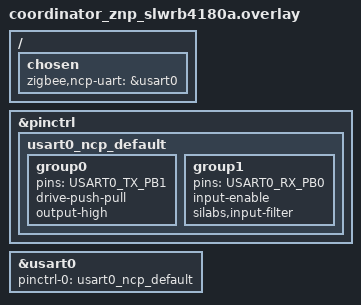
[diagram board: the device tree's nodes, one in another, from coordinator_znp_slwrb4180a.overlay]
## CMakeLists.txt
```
# SPDX-FileCopyrightText: Copyright The Zephyr Project Contributors
# SPDX-License-Identifier: Apache-2.0
cmake_minimum_required(VERSION 3.20)
find_package(Zephyr REQUIRED HINTS $ENV{ZEPHYR_BASE})
project(zigbee_shell)
target_sources(app PRIVATE
  src/main.c
  src/app_bdb.c
  src/app_profile.c
)

if(CONFIG_BOARD_PROMICRO_NRF52840 AND CONFIG_SHELL)
  target_sources(app PRIVATE src/board_promicro_nrf52840.c)
endif()

if(CONFIG_BOARD_WEACT_STM32WB55_CORE)
  # USB CDC console and mcumgr, watchdog and the flash state fix of the board; the same
  # fix is built into its MCUboot, see mcuboot/
  if(CONFIG_USB_DEVICE_STACK_NEXT)
    include(${ZEPHYR_BASE}/samples/subsys/usb/common/common.cmake)
  endif()
  target_sources(app PRIVATE
    src/board_weact_stm32wb55_core.c
    mcuboot/wbfix/wbfix.c
  )
endif()

# Expose ZCL SDK headers (zcl/, af/) that live under subsys/zigbee but are
# not part of the public zephyr_include_directories set.
target_include_directories(app PRIVATE
    ${ZEPHYR_BASE}/subsys/zigbee
    ${ZEPHYR_BASE}/subsys/zigbee/include
    ${ZEPHYR_BASE}/subsys/zigbee/common/includes
    ${ZEPHYR_BASE}/subsys/zigbee/platform/zephyr
)
```

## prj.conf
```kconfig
# SPDX-FileCopyrightText: Copyright The Zephyr Project Contributors
# SPDX-License-Identifier: Apache-2.0

CONFIG_ZIGBEE=y
CONFIG_ZIGBEE_ED=y
CONFIG_ZIGBEE_BDB=y
CONFIG_ZIGBEE_ZCL=y
CONFIG_ZIGBEE_GP=n
CONFIG_ZIGBEE_OTA=n
CONFIG_ZIGBEE_WWAH=n
# k_sys_fatal_error_handler() reboots instead of spinning forever on a
# fault/assert -- required so SYSTEM_RESET() (zb_main.c) links.
CONFIG_REBOOT=y
CONFIG_NETWORKING=y
CONFIG_NET_L2_CUSTOM_IEEE802154=y
CONFIG_NET_TC_RX_COUNT=0
CONFIG_NET_IPV4=n
CONFIG_NET_IPV6=n
CONFIG_NET_UDP=n
CONFIG_NET_TCP=n
CONFIG_NET_SOCKETS=n
CONFIG_IEEE802154=y
CONFIG_IEEE802154_L2_PKT_INCL_FCS=n
CONFIG_CONSOLE=n
CONFIG_UART_CONSOLE=n
CONFIG_SERIAL=n
CONFIG_PRINTK=n
CONFIG_NVS=y
CONFIG_FLASH=y
CONFIG_FLASH_MAP=y
CONFIG_LOG=n
CONFIG_MAIN_STACK_SIZE=896
CONFIG_SYSTEM_WORKQUEUE_STACK_SIZE=1024
# Keep the packet pools small; Zigbee consumes RX packets in its own thread.
CONFIG_NET_BUF_RX_COUNT=2
CONFIG_NET_BUF_TX_COUNT=2
```

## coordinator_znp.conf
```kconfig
# SPDX-FileCopyrightText: Copyright The Zephyr Project Contributors
# SPDX-License-Identifier: Apache-2.0

# A coordinator that a Z-Stack host (Zigbee2MQTT, ZHA) drives over the UART
# the board overlay names as zigbee,ncp-uart.
CONFIG_ZIGBEE_COORDINATOR=y
CONFIG_ZIGBEE_NCP=y
CONFIG_ZIGBEE_NCP_ZSTACK=y
CONFIG_ZIGBEE_STACK_SIZE=4096
```

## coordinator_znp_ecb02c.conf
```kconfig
# SPDX-FileCopyrightText: Copyright The Zephyr Project Contributors
# SPDX-License-Identifier: Apache-2.0

# The console UART is the host UART: no shell and no log on it
CONFIG_SHELL=n
CONFIG_KERNEL_SHELL=n

# The UART has a 16-byte receive FIFO: collect the requests in the interrupt
CONFIG_ZIGBEE_NCP_ZSTACK_UART_IRQ=y
```

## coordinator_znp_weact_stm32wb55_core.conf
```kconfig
# SPDX-FileCopyrightText: Copyright The Zephyr Project Contributors
# SPDX-License-Identifier: Apache-2.0

# The first USB CDC port is the host UART: no console, shell or log on it
CONFIG_SHELL=n
CONFIG_SHELL_BACKEND_SERIAL=n
CONFIG_SHELL_LOG_BACKEND=n
CONFIG_LOG=n
CONFIG_CONSOLE=n
CONFIG_PRINTK=n
```

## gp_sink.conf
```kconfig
# SPDX-FileCopyrightText: Copyright The Zephyr Project Contributors
# SPDX-License-Identifier: Apache-2.0

# Green Power proxy and sink; use with router.conf.
CONFIG_ZIGBEE_GP=y
CONFIG_ZIGBEE_GP_SINK=y
CONFIG_GPIO=y
```

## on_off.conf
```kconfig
# SPDX-FileCopyrightText: Copyright The Zephyr Project Contributors
# SPDX-License-Identifier: Apache-2.0

# On/Off light server driving led0.
CONFIG_ZIGBEE_ZCL_ON_OFF=y
CONFIG_GPIO=y
```

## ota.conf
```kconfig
# SPDX-FileCopyrightText: Copyright The Zephyr Project Contributors
# SPDX-License-Identifier: Apache-2.0

# Use together with -S tlsr8258-mcuboot.
CONFIG_ZIGBEE_OTA=y
CONFIG_LOG=y
```

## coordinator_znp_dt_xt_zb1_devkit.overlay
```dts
/*
 * SPDX-FileCopyrightText: Copyright The Zephyr Project Contributors
 * SPDX-License-Identifier: Apache-2.0
 */

/* Z-Stack host UART for dt_xt_zb1_devkit: uart0 (GPIO14 TX, GPIO15 RX), the
 * board's only UART. The coordinator build turns the console off, so the UART
 * carries only the NCP protocol.
 */

/ {
	chosen {
		zigbee,ncp-uart = &uart0;
	};
};
```

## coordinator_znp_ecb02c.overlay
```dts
/*
 * SPDX-FileCopyrightText: Copyright The Zephyr Project Contributors
 * SPDX-License-Identifier: Apache-2.0
 */

/* Z-Stack host UART for ecb02c: uart1 (P3 TX, P2 RX), the module's console UART and the one its
 * USB-UART is wired to. The coordinator build turns the console and the shell off, so the UART
 * carries only the NCP protocol.
 */

/ {
	chosen {
		zigbee,ncp-uart = &uart1;
	};
};
```

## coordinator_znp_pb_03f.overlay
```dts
/*
 * SPDX-FileCopyrightText: Copyright The Zephyr Project Contributors
 * SPDX-License-Identifier: Apache-2.0
 */

/* Z-Stack host UART for pb_03f: uart0, the board's only UART. The coordinator
 * build turns the console off, so the UART carries only the NCP protocol.
 */

/ {
	chosen {
		zigbee,ncp-uart = &uart0;
	};
};
```

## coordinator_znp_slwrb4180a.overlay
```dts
/*
 * SPDX-FileCopyrightText: Copyright The Zephyr Project Contributors
 * SPDX-License-Identifier: Apache-2.0
 */

/* Z-Stack host UART for slwrb4180a: USART0 on PB0 (RX) and PB1 (TX). The
 * coordinator build turns the console off, so the UART carries only the NCP
 * protocol. Router and end device builds keep the board's default pins.
 */

#include <zephyr/dt-bindings/pinctrl/silabs/xg21-pinctrl.h>

&pinctrl {
	usart0_ncp_default: usart0_ncp_default {
		group0 {
			pins = <USART0_TX_PB1>;
			drive-push-pull;
			output-high;
		};

		group1 {
			pins = <USART0_RX_PB0>;
			input-enable;
			silabs,input-filter;
		};
	};
};

&usart0 {
	pinctrl-0 = <&usart0_ncp_default>;
	pinctrl-names = "default";
};

/ {
	chosen {
		zigbee,ncp-uart = &usart0;
	};
};
```

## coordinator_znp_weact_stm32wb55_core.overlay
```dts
/*
 * SPDX-FileCopyrightText: Copyright The Zephyr Project Contributors
 * SPDX-License-Identifier: Apache-2.0
 */

/* The first USB CDC port carries the Z-Stack host protocol of coordinator_znp.conf: the board
 * is a USB coordinator. The second one stays the mcumgr port.
 */
/ {
	chosen {
		zigbee,ncp-uart = &cdc_acm_uart0;
	};
};
```

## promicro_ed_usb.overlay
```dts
/*
 * SPDX-FileCopyrightText: Copyright The Zephyr Project Contributors
 * SPDX-License-Identifier: Apache-2.0
 */

&app_partition_nosd {
	reg = <0x1000 0xdb000>;
};

&flash0 {
	partitions {
		zigbee_nv_partition: partition@dc000 {
			compatible = "zephyr,mapped-partition";
			label = "zigbee_ed_nv";
			reg = <0xdc000 0x8000>;
		};
	};
};
```

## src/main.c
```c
/*
 * SPDX-FileCopyrightText: Copyright The Zephyr Project Contributors
 * SPDX-License-Identifier: Apache-2.0
 */
/*
 * main.c — Zephyr bootstrap hook surface for the zigbee_shell sample.
 *
 * This file implements only the zb_platform_app_* callbacks required by
 * the Zigbee platform bootstrap thread.  All commissioning / BDB policy
 * lives in app_bdb.c; all endpoint / profile / ZCL wiring lives in
 * app_profile.c.
 */
#include <zephyr/device.h>
#include <zephyr/devicetree.h>
#include <zephyr/kernel.h>
#include <zephyr/logging/log.h>
#include <zephyr/zigbee/zb_bootstrap.h>
#include <zephyr/zigbee/zb_channel.h>
#include <zephyr/zigbee/zb_config.h>
#if defined(CONFIG_ZIGBEE_ZSTACK_NCP)
#include <zephyr/zigbee/zb_znp.h>

BUILD_ASSERT(DT_HAS_CHOSEN(zigbee_ncp_uart),
	     "the board overlay must name the host UART as zigbee,ncp-uart");
#endif

#include "app_bdb.h"
#include "app_profile.h"

LOG_MODULE_REGISTER(main);

#if !defined(CONFIG_ZIGBEE_BDB)
static bool radio_validation_started;
static struct k_work_delayable radio_probe_work;

static void zigbee_shell_radio_probe(struct k_work *work)
{
	struct zb_platform_radio_diag_snapshot snapshot;
	int rc;

	ARG_UNUSED(work);

	rc = zb_platform_radio_start_on_channel(ZB_CHANNEL_INITIAL);
	if (rc < 0) {
		LOG_ERR("radio probe start failed (ch=%d rc=%d)", ZB_CHANNEL_INITIAL, rc);
		goto reschedule;
	}

	rc = zb_platform_radio_send_beacon_request();
	if (rc < 0) {
		LOG_ERR("radio probe beacon request failed (rc=%d)", rc);
	}

	if (zb_platform_radio_diag_get(&snapshot) == 0) {
		LOG_INF("radio diag: ch=%u started=%u tx=%u/%u fail=%u rx=%u drop=%u err=%u "
			"rssi=%d",
			snapshot.channel, snapshot.started, snapshot.tx_success,
			snapshot.tx_attempts, snapshot.tx_failures, snapshot.rx_accept_count,
			snapshot.rx_drop_count, snapshot.last_error, snapshot.last_rx_rssi_dbm);
	}

reschedule:
	(void)k_work_schedule(&radio_probe_work, K_SECONDS(1));
}
#endif

bool zb_platform_app_get_join_profile(struct zb_platform_bdb_join_profile *profile)
{
	return app_bdb_get_join_profile(profile);
}

void zb_platform_app_bootstrap_ready(void)
{
#if !defined(CONFIG_ZIGBEE_BDB)
	if (!radio_validation_started) {
		k_work_init_delayable(&radio_probe_work, zigbee_shell_radio_probe);
		radio_validation_started = true;
		(void)k_work_schedule(&radio_probe_work, K_MSEC(250));
		LOG_INF("zigbee_shell radio validation scheduled on channel %d",
			ZB_CHANNEL_INITIAL);
	}
#endif
	app_bdb_bootstrap_ready();
}

bool zb_platform_app_enable_radio_smoke_probe(void)
{
	/* Keep smoke probe as opt-in diagnostics only. */
	return false;
}

bool zb_platform_app_should_start_commissioning(void)
{
#if defined(CONFIG_ZIGBEE_ZSTACK_NCP)
	/* The host starts network formation. */
	return false;
#else
	return app_bdb_should_start_commissioning();
#endif
}

void zb_platform_app_start_commissioning(void)
{
	app_bdb_start_commissioning();
}

void zb_platform_app_network_left(void)
{
	app_bdb_network_left();
}

void zb_platform_app_bdb_commissioning_status(uint8_t status, bool joinedNetwork)
{
	app_bdb_commissioning_status(status, joinedNetwork);
#if defined(CONFIG_ZIGBEE_ZSTACK_NCP)
	zb_znp_bdb_commissioning_status(status, joinedNetwork);
#endif
}

int main(void)
{
#if defined(CONFIG_ZIGBEE_ZSTACK_NCP)
	/* The board overlay names the UART the Z-Stack host is attached to. */
	int rc = zb_znp_init(DEVICE_DT_GET(DT_CHOSEN(zigbee_ncp_uart)));

	if (rc != 0) {
		LOG_ERR("ZNP UART init failed (%d)", rc);
	}
#endif
	if (IS_ENABLED(CONFIG_ZIGBEE_RUN_IN_MAIN)) {
		zb_main_run();
	}

	return 0;
}
```

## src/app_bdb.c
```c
/*
 * SPDX-FileCopyrightText: Copyright The Zephyr Project Contributors
 * SPDX-License-Identifier: Apache-2.0
 */
/*
 * app_bdb.c — Commissioning / rejoin / poll-rate / leave policy for the
 * zigbee_shell sample.
 *
 * Contains all runtime BDB state that was previously inlined in main.c.
 * main.c delegates each zb_platform_app_* hook to the functions here.
 */

#include "app_bdb.h"
#include "app_profile.h"

#include <string.h>
#include <zephyr/kernel.h>
#include <zephyr/logging/log.h>
#include <zephyr/zigbee/zb_bootstrap.h>
#include <zephyr/zigbee/zb_channel.h>
#include <zephyr/zigbee/zb_config.h>

#if !defined(ZDO_ZCL_STUBS_H_)
/*
 * Production build: pull in the real SDK headers for ZDO/ZCL types and
 * constants.  In the host test harness zdo_zcl_stubs.h is pre-included
 * before app_bdb.c, so this block is deliberately skipped there.
 */
#include "zbapi/zb_api.h"
#include "zcl/zcl_config.h"
#include "zcl/zcl.h"
#endif

LOG_MODULE_REGISTER(app_bdb);

#if defined(CONFIG_ZIGBEE_ROUTER) || defined(CONFIG_ZIGBEE_COORDINATOR)
#define APP_BDB_ROLE_ROUTER 1
#define APP_BDB_ROLE_ED     0
#else
#define APP_BDB_ROLE_ROUTER 0
#define APP_BDB_ROLE_ED     1
#endif

typedef int (*app_bdb_timer_callback_t)(void *data);

struct ev_timer_event_t;

extern struct ev_timer_event_t *ev_timer_taskPost(app_bdb_timer_callback_t func, void *arg,
						  uint32_t t_ms);
extern uint8_t ev_timer_taskCancel(struct ev_timer_event_t **evt);
extern uint8_t zb_routerStart(void);
#if APP_BDB_ROLE_ROUTER
/*
 * Open the FFD as a parent after it joins so other devices can join through
 * it. 0xff = permit-join permanently.
 */
extern void zb_router_enable_parenting(uint8_t permit_duration);
#endif

#define APP_BDB_COMMISSIONING_RETRY_MS 5000U

#if defined(CONFIG_ZIGBEE_BDB)
static bool commissioning_start_requested;
static bool bdb_runtime_ready;
static bool leave_recommission_pending;
static struct ev_timer_event_t *commissioning_retry_timer;
static const uint8_t app_bdb_fixed_tc_addr[8] = {
	0x0c, 0x80, 0x1e, 0xfe, 0xff, 0x16, 0xa7, 0x20,
};

extern bool zb_isDeviceJoinedNwk(void);
extern bool zdo_ifZdoNwkManagerIdle(void);
extern uint8_t zb_setPollRate(uint32_t newRate);
extern uint32_t zb_getPollRate(void);

static void app_bdb_activate_poll_rate(void)
{
#if APP_BDB_ROLE_ED
	uint32_t poll_rate = zb_getPollRate();

	if (poll_rate == 0U) {
		poll_rate = POLL_RATE;
	}

	(void)zb_setPollRate(poll_rate);
#endif
}

static void app_bdb_commissioning_retry_schedule(void);
static void app_bdb_commissioning_retry_cancel(void);
/* forward declaration so retry handler can call it */
void app_bdb_start_commissioning(void);

static int app_bdb_commissioning_retry(void *data)
{
	bool joined = zb_isDeviceJoinedNwk();
	bool idle = zdo_ifZdoNwkManagerIdle();

	ARG_UNUSED(data);
	commissioning_retry_timer = NULL;

	if (leave_recommission_pending) {
		if (!bdb_runtime_ready || joined || commissioning_start_requested) {
			app_bdb_commissioning_retry_schedule();
			return -1;
		}

		leave_recommission_pending = false;
		app_bdb_start_commissioning();
		if (!commissioning_start_requested) {
			leave_recommission_pending = true;
			app_bdb_commissioning_retry_schedule();
		}
		return -1;
	}

	if (joined) {
		app_bdb_activate_poll_rate();
		commissioning_start_requested = true;
#if APP_BDB_ROLE_ROUTER
		zb_router_enable_parenting(0xffU);
#endif
		return -1;
	}
	if (!idle) {
		commissioning_start_requested = true;
		app_bdb_commissioning_retry_schedule();
		return -1;
	}

	commissioning_start_requested = false;
	app_bdb_start_commissioning();
	return -1;
}

static void app_bdb_commissioning_retry_cancel(void)
{
	if (commissioning_retry_timer != NULL) {
		(void)ev_timer_taskCancel(&commissioning_retry_timer);
		commissioning_retry_timer = NULL;
	}
}

static void app_bdb_commissioning_retry_schedule(void)
{
	app_bdb_commissioning_retry_cancel();
	commissioning_retry_timer = ev_timer_taskPost(app_bdb_commissioning_retry, NULL,
						      APP_BDB_COMMISSIONING_RETRY_MS);
}
#endif /* CONFIG_ZIGBEE_BDB */

void zb_platform_app_runtime_reset(void)
{
#if defined(CONFIG_ZIGBEE_BDB)
	commissioning_start_requested = false;
	bdb_runtime_ready = false;
	leave_recommission_pending = false;
	commissioning_retry_timer = NULL;
#endif
}

/* ------------------------------------------------------------------ */
/* Public API                                                          */
/* ------------------------------------------------------------------ */

bool app_bdb_get_join_profile(struct zb_platform_bdb_join_profile *profile)
{
#if !defined(CONFIG_ZIGBEE_BDB)
	ARG_UNUSED(profile);
	return false;
#else
	if (profile == NULL) {
		return false;
	}

	memset(profile, 0, sizeof(*profile));
	profile->channel_mask = (uint32_t)ZB_CHANNEL_SCAN_MASK;
	/*
	 * Real network joins must learn the NWK key during interview via the
	 * Trust Center Transport Key exchange.  Do not preload a test key
	 * here: it short-circuits interview and breaks live-network joins.
	 */
	profile->network_key_valid = false;
	if (APP_BDB_ROLE_ED) {
		memcpy(profile->tc_addr, app_bdb_fixed_tc_addr, sizeof(app_bdb_fixed_tc_addr));
		profile->tc_addr_valid = true;
	}

	return true;
#endif
}

void app_bdb_bootstrap_ready(void)
{
#if defined(CONFIG_ZIGBEE_BDB)
	if (bdb_runtime_ready && g_bdbCtx.simpleDesc == NULL) {
		/*
		 * The platform clears g_zbInfo before rebuilding the stack, but
		 * retained SRAM can preserve this application-level guard.
		 */
		bdb_runtime_ready = false;
		commissioning_start_requested = false;
		leave_recommission_pending = false;
		commissioning_retry_timer = NULL;
	}

	if (!bdb_runtime_ready) {
		int err = zb_platform_bdb_init_default();
		bool joined = zb_isDeviceJoinedNwk();
		bool idle = zdo_ifZdoNwkManagerIdle();

		if (err == 0) {
			bdb_runtime_ready = true;
			if (joined && idle && APP_BDB_ROLE_ED) {
				app_bdb_activate_poll_rate();
			}
#if APP_BDB_ROLE_ROUTER
			/*
			 * A restored router is already an always-on FFD.  Do not send it
			 * through the ED persistent-rejoin path; announce the restored
			 * short address and keep RX open for the coordinator interview.
			 */
			if (joined && idle) {
				zb_router_enable_parenting(0xffU);
			}
#endif
		} else {
			LOG_ERR("zigbee_shell BDB runtime init failed (%d)", err);
		}
	}
#endif
}

bool app_bdb_should_start_commissioning(void)
{
#if defined(CONFIG_ZIGBEE_BDB)
	bool should_start;

	if (!bdb_runtime_ready) {
		return false;
	}
	if (commissioning_start_requested) {
		return false;
	}

	should_start = !zb_isDeviceJoinedNwk();
	return should_start;
#else
	return false;
#endif
}

void app_bdb_start_commissioning(void)
{
#if defined(CONFIG_ZIGBEE_BDB)
	uint8_t status;

	if (!bdb_runtime_ready) {
		LOG_WRN("zigbee_shell commissioning start: BDB runtime not initialized");
		return;
	}

	if (commissioning_start_requested) {
		LOG_WRN("zigbee_shell commissioning start: already requested");
		return;
	}

	if (zb_isDeviceJoinedNwk()) {
		commissioning_start_requested = true;
		if (APP_BDB_ROLE_ED) {
			app_bdb_activate_poll_rate();
		}
		app_bdb_commissioning_retry_cancel();
		return;
	}

#if defined(CONFIG_ZIGBEE_COORDINATOR)
	status = zb_platform_bdb_network_formation_start();
#else
	status = zb_platform_bdb_network_steer_start();
#endif
	if (status == 0U) {
		commissioning_start_requested = true;
		if (zb_isDeviceJoinedNwk()) {
			app_bdb_commissioning_retry_cancel();
		}
		if (!zb_isDeviceJoinedNwk()) {
			app_bdb_commissioning_retry_schedule();
		}
		/*
		 * Keep this path non-blocking: the Zigbee thread must return to the
		 * scheduler so the queued BDB start task can run immediately.
		 */
	} else {
		commissioning_start_requested = false;
		app_bdb_commissioning_retry_schedule();
	}
#endif
}

void app_bdb_network_left(void)
{
#if defined(CONFIG_ZIGBEE_BDB)
	commissioning_start_requested = false;
	leave_recommission_pending = true;
	app_bdb_commissioning_retry_cancel();
	app_bdb_commissioning_retry_schedule();
#endif
}

/*
 * Callback fired by the ZDO layer when the coordinator's Active_EP_rsp
 * arrives.  Drives the interview: issues SimpleDesc + Basic-cluster read
 * for each endpoint reported by the coordinator.
 *
 * `p` is a `zdo_zdpDataInd_t *` allocated by the ZDO layer with `zpdu`
 * pointing at the raw Active_EP_rsp payload (seq, status, nwk_addr,
 * ep_count, ep_list[]).  This is the same contract used by bdb.c callbacks.
 */
static void app_bdb_active_ep_rsp_cb(void *p)
{
	const zdo_zdpDataInd_t *ind = (const zdo_zdpDataInd_t *)p;
	const zdo_active_ep_resp_t *rsp;
	uint8_t i;

	if ((ind == NULL) || (ind->zpdu == NULL)) {
		return;
	}

	rsp = (const zdo_active_ep_resp_t *)ind->zpdu;
	if (ind->status != (uint8_t)ZDO_SUCCESS || rsp->active_ep_count == 0U) {
		return;
	}

	for (i = 0U; i < rsp->active_ep_count && i < MAX_REQUESTED_CLUSTER_NUMBER; i++) {
		zdo_simple_descriptor_req_t sd_req;
		epInfo_t ep_info;
		struct {
			uint8_t numAttr;
			uint16_t attrID[2];
		} basic_read = {2U, {0x0004U, 0x0005U}};
		uint8_t seq = 0U;
		uint8_t ep = rsp->active_ep_lst[i];

		sd_req.nwk_addr_interest = ind->src_addr;
		sd_req.endpoint = ep;
		(void)zb_zdoSimpleDescReq(ind->src_addr, &sd_req, &seq, NULL);

		memset(&ep_info, 0, sizeof(ep_info));
		ep_info.dstAddr.shortAddr = ind->src_addr;
		ep_info.dstEp = ep;
		ep_info.profileId = APP_PROFILE_HA_PROFILE_ID;
		ep_info.dstAddrMode = APS_SHORT_DSTADDR_WITHEP;
		ep_info.txOptions = APS_TX_OPT_ACK_TX;
		ep_info.radius = 30U;
		seq = 0U;
		(void)zcl_read(APP_PROFILE_ENDPOINT, &ep_info, 0x0000U, 0U, 1U, 0U, seq,
			       (zclReadCmd_t *)&basic_read);
	}
}

void app_bdb_commissioning_status(uint8_t status, bool joinedNetwork)
{
#if defined(CONFIG_ZIGBEE_BDB)
	if (joinedNetwork) {
		if (APP_BDB_ROLE_ED) {
			app_bdb_activate_poll_rate();
		}
		leave_recommission_pending = false;
		commissioning_start_requested = true;
		app_bdb_commissioning_retry_cancel();
		if (APP_BDB_ROLE_ED && status == 0x00U) {
			/*
			 * Post-join ZDO/ZCL interview: discover coordinator endpoints.
			 * The response callback app_bdb_active_ep_rsp_cb will issue
			 * SimpleDesc + Basic-cluster read for each discovered endpoint,
			 * making the interview flow response-driven rather than hardcoded.
			 */
			zdo_active_ep_req_t ep_req = {.nwk_addr_interest = 0x0000U};
			uint8_t seq = 0U;

			(void)zb_zdoActiveEpReq(0x0000U, &ep_req, &seq, app_bdb_active_ep_rsp_cb);
		}
#if APP_BDB_ROLE_ROUTER
		/*
		 * We are now in the network — open ourselves as a parent so
		 * other devices can join THROUGH this router.
		 */
		zb_router_enable_parenting(0xffU);
#endif
		LOG_INF("zigbee_shell joined network (bdb status: 0x%02x)", status);
		return;
	}

	if (zb_isDeviceJoinedNwk()) {
		if (APP_BDB_ROLE_ED) {
			app_bdb_activate_poll_rate();
		}
		leave_recommission_pending = false;
		commissioning_start_requested = true;
		app_bdb_commissioning_retry_cancel();
#if APP_BDB_ROLE_ROUTER
		/* Joined (per state check) — open ourselves as a parent. */
		zb_router_enable_parenting(0xffU);
#endif
		LOG_INF("zigbee_shell joined network after status check (bdb status: 0x%02x)",
			status);
		return;
	}

	commissioning_start_requested = false;
	if (APP_BDB_ROLE_ROUTER) {
		LOG_INF("zigbee_shell router commissioning pending (bdb status: 0x%02x), retry "
			"scheduled",
			status);
	} else {
		LOG_INF("zigbee_shell not joined yet (bdb status: 0x%02x), retry scheduled",
			status);
	}
	app_bdb_commissioning_retry_schedule();
#else
	ARG_UNUSED(status);
	ARG_UNUSED(joinedNetwork);
#endif
}
```

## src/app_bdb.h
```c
/*
 * SPDX-FileCopyrightText: Copyright The Zephyr Project Contributors
 * SPDX-License-Identifier: Apache-2.0
 */
/*
 * app_bdb.h — Commissioning / rejoin / poll-rate / leave policy for the
 * zigbee_shell sample.
 *
 * The functions declared here are the implementations of the
 * zb_platform_app_* bootstrap hooks.  main.c delegates to them so it
 * stays thin.
 */
#pragma once

#include <stdbool.h>
#include <stdint.h>

#include <zephyr/zigbee/zb_bootstrap.h>

void app_bdb_bootstrap_ready(void);
bool app_bdb_should_start_commissioning(void);
void app_bdb_start_commissioning(void);
void app_bdb_network_left(void);
void app_bdb_commissioning_status(uint8_t status, bool joinedNetwork);
bool app_bdb_get_join_profile(struct zb_platform_bdb_join_profile *profile);
```

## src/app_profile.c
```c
/*
 * SPDX-FileCopyrightText: Copyright The Zephyr Project Contributors
 * SPDX-License-Identifier: Apache-2.0
 */
/*
 * app_profile.c — ZCL endpoint registration for the zigbee_shell sample.
 *
 * Owns the authoritative endpoint descriptor, Basic/Identify attribute
 * tables, and the single app_profile_register() entry point that wires
 * the ZCL and AF layers together.
 *
 * Reference pattern: tl_zigbee_sdk/apps/sampleSwitch/sampleSwitch.c
 *   zcl_init(hook)
 *   af_endpointRegister(ep, &desc, zcl_rx_handler, NULL)
 *   zcl_register(ep, N, clusters)
 */

#include "app_profile.h"

#include <string.h>

/*
 * In a real Zephyr build pull in the ZCL/AF SDK headers.
 * In the host-test harness the test file provides all stubs before
 * including this translation unit, so no SDK headers are needed.
 */
#if defined(__ZEPHYR__)
#include <zephyr/logging/log.h>
LOG_MODULE_REGISTER(app_profile);
/*
 * Pull in SDK compiler/type shims before ZCL/AF headers.
 * compiler_zephyr.h defines _attribute_packed_ -> __packed so that
 * the SDK's "typedef struct _attribute_packed_ {...}" pattern produces
 * anonymous packed structs instead of a struct named _attribute_packed_.
 * zb_types.h provides u8/u16/u32 which ZCL/AF headers use but do not
 * include themselves.
 * af/zb_af.h defines epInfo_t which zcl.h uses in function declarations.
 */
#include "platform/zephyr/compiler_zephyr.h"
#include <zephyr/zigbee/zb_types.h>
#include "af/zb_af.h"
#include "zcl/zcl_const.h"
#include "zcl/zcl.h"
#include "zcl/general/zcl_basic.h"
#include "zcl/general/zcl_identify.h"
void zcl_rx_handler(void *p);
#if defined(CONFIG_ZIGBEE_GP)
/*
 * gp/gp.h needs SEC_KEY_LEN (zb_config.h) and the gpSwitchInfo_t/
 * zcl_gp_*Cmd_t types (zcl_greenPower.h) that the piecemeal ZCL includes
 * above do not pull in; gp.c itself gets them via the full zcl_include.h.
 */
#include <zephyr/zigbee/zb_config.h>
#include "zcl/general/zcl_greenPower.h"
#include "gp/gp.h"
#endif
#if defined(CONFIG_ZIGBEE_OTA)
#include "ota/ota.h"
#endif
#if defined(CONFIG_ZIGBEE_WWAH)
#include "wwah/wwah.h"
#endif
#if defined(CONFIG_ZIGBEE_ZCL_ON_OFF)
#include <zephyr/drivers/gpio.h>
#include "zcl/general/zcl_onoff.h"
#endif
#endif /* __ZEPHYR__ */

/* ------------------------------------------------------------------ */
/* Basic cluster attribute table                                       */
/* ------------------------------------------------------------------ */

/* ZCL CHAR_STR encoding: first byte is length, then the characters.  */
static const u8 app_basic_zcl_ver = 3U;
static const u8 app_basic_app_ver = 1U;
static const u8 app_basic_stack_ver = 2U;
static const u8 app_basic_hw_ver = 1U;
static const u8 app_basic_power_src = 0x03U; /* Battery (0x03) */
static const u16 app_basic_cluster_rev = ZCL_ATTR_GLOBAL_CLUSTER_REVISION_DEFAULT;

/* Manufacturer name and model ID as ZCL CHAR_STR (length-prefixed). */
static u8 app_basic_mfr_name[1U + sizeof(APP_PROFILE_MFR_NAME)] = {
	sizeof(APP_PROFILE_MFR_NAME) - 1U,
};

static u8 app_basic_model_id[1U + sizeof(APP_PROFILE_MODEL_ID)] = {
	sizeof(APP_PROFILE_MODEL_ID) - 1U,
};

static const zclAttrInfo_t app_basic_attr_tbl[] = {
	{ZCL_ATTRID_BASIC_ZCL_VER, ZCL_DATA_TYPE_UINT8, ACCESS_CONTROL_READ,
	 (u8 *)&app_basic_zcl_ver},
	{ZCL_ATTRID_BASIC_APP_VER, ZCL_DATA_TYPE_UINT8, ACCESS_CONTROL_READ,
	 (u8 *)&app_basic_app_ver},
	{ZCL_ATTRID_BASIC_STACK_VER, ZCL_DATA_TYPE_UINT8, ACCESS_CONTROL_READ,
	 (u8 *)&app_basic_stack_ver},
	{ZCL_ATTRID_BASIC_HW_VER, ZCL_DATA_TYPE_UINT8, ACCESS_CONTROL_READ,
	 (u8 *)&app_basic_hw_ver},
	{ZCL_ATTRID_BASIC_MFR_NAME, ZCL_DATA_TYPE_CHAR_STR, ACCESS_CONTROL_READ,
	 (u8 *)app_basic_mfr_name},
	{ZCL_ATTRID_BASIC_MODEL_ID, ZCL_DATA_TYPE_CHAR_STR, ACCESS_CONTROL_READ,
	 (u8 *)app_basic_model_id},
	{ZCL_ATTRID_BASIC_POWER_SOURCE, ZCL_DATA_TYPE_ENUM8, ACCESS_CONTROL_READ,
	 (u8 *)&app_basic_power_src},
	{ZCL_ATTRID_GLOBAL_CLUSTER_REVISION, ZCL_DATA_TYPE_UINT16, ACCESS_CONTROL_READ,
	 (u8 *)&app_basic_cluster_rev},
};

#define APP_BASIC_ATTR_NUM ((u8)ARRAY_SIZE(app_basic_attr_tbl))

/* ------------------------------------------------------------------ */
/* Identify cluster attribute table                                    */
/* ------------------------------------------------------------------ */

static u16 app_identify_time;
static const u16 app_identify_cluster_rev = ZCL_ATTR_GLOBAL_CLUSTER_REVISION_DEFAULT;

static const zclAttrInfo_t app_identify_attr_tbl[] = {
	{ZCL_ATTRID_IDENTIFY_TIME, ZCL_DATA_TYPE_UINT16, ACCESS_CONTROL_READ,
	 (u8 *)&app_identify_time},
	{ZCL_ATTRID_GLOBAL_CLUSTER_REVISION, ZCL_DATA_TYPE_UINT16, ACCESS_CONTROL_READ,
	 (u8 *)&app_identify_cluster_rev},
};

#define APP_IDENTIFY_ATTR_NUM                                                                      \
	((u8)ARRAY_SIZE(app_identify_attr_tbl))

#if defined(CONFIG_ZIGBEE_ZCL_ON_OFF)
/* ------------------------------------------------------------------ */
/* On/Off cluster: drives the board's led0                             */
/* ------------------------------------------------------------------ */

static const struct gpio_dt_spec app_led = GPIO_DT_SPEC_GET(DT_ALIAS(led0), gpios);
static bool app_onoff_state;
static const u16 app_onoff_cluster_rev = ZCL_ATTR_GLOBAL_CLUSTER_REVISION_DEFAULT;

static const zclAttrInfo_t app_onoff_attr_tbl[] = {
	{ZCL_ATTRID_ONOFF, ZCL_DATA_TYPE_BOOLEAN, ACCESS_CONTROL_READ | ACCESS_CONTROL_REPORTABLE,
	 (u8 *)&app_onoff_state},
	{ZCL_ATTRID_GLOBAL_CLUSTER_REVISION, ZCL_DATA_TYPE_UINT16, ACCESS_CONTROL_READ,
	 (u8 *)&app_onoff_cluster_rev},
};

#define APP_ONOFF_ATTR_NUM ((u8)ARRAY_SIZE(app_onoff_attr_tbl))

static void app_onoff_set(bool on)
{
	app_onoff_state = on;
	gpio_pin_set_dt(&app_led, on ? 1 : 0);
	zcl_setAttrVal(APP_PROFILE_ENDPOINT, ZCL_CLUSTER_GEN_ON_OFF, ZCL_ATTRID_ONOFF,
		       (u8 *)&app_onoff_state);
}

static status_t app_onoff_cmd(zclIncomingAddrInfo_t *addr_info, u8 cmd_id, void *payload)
{
	ARG_UNUSED(addr_info);
	ARG_UNUSED(payload);

	switch (cmd_id) {
	case ZCL_CMD_ONOFF_ON:
		app_onoff_set(true);
		break;
	case ZCL_CMD_ONOFF_OFF:
		app_onoff_set(false);
		break;
	case ZCL_CMD_ONOFF_TOGGLE:
		app_onoff_set(!app_onoff_state);
		break;
	default:
		return ZCL_STA_UNSUP_CLUSTER_COMMAND;
	}

	return ZCL_STA_SUCCESS;
}
#endif /* CONFIG_ZIGBEE_ZCL_ON_OFF */

/* ------------------------------------------------------------------ */
/* In-cluster list and simple descriptor                               */
/* ------------------------------------------------------------------ */

static u16 app_in_clusters[] = {
	ZCL_CLUSTER_GEN_BASIC,
	ZCL_CLUSTER_GEN_IDENTIFY,
#if defined(CONFIG_ZIGBEE_ZCL_ON_OFF)
	ZCL_CLUSTER_GEN_ON_OFF,
#endif
#if defined(CONFIG_ZIGBEE_WWAH)
	ZCL_CLUSTER_WWAH,
#endif
};

#if defined(CONFIG_ZIGBEE_OTA)
static u16 app_out_clusters[] = {
	ZCL_CLUSTER_OTA,
};
#endif

static af_simple_descriptor_t app_simple_desc = {
	.app_profile_id = APP_PROFILE_HA_PROFILE_ID,
	.app_dev_id = APP_PROFILE_HA_DEVICE_ID,
	.endpoint = APP_PROFILE_ENDPOINT,
	.app_dev_ver = 1U,
	.reserved = 0U,
	.app_in_cluster_count = ARRAY_SIZE(app_in_clusters),
#if defined(CONFIG_ZIGBEE_OTA)
	.app_out_cluster_count = 1U,
	.app_in_cluster_lst = app_in_clusters,
	.app_out_cluster_lst = app_out_clusters,
#else
	.app_out_cluster_count = 0U,
	.app_in_cluster_lst = app_in_clusters,
	.app_out_cluster_lst = NULL,
#endif
};

#if defined(CONFIG_ZIGBEE_OTA)
/*
 * Identity the server matches the OTA file against: raise file_ver with
 * every release, and keep image_type and manufacturer_code equal to the OTA
 * file header. totalImageSize is unused by the client.
 */
static ota_preamble_t app_ota_preamble = {
	.fileVer = 0x00000001U,
	.totalImageSize = 0U,
	.imageType = 0x0001U,
	.manufacturerCode = 0x1141U,
};

static void app_ota_event(u8 evt, u8 status)
{
	if ((evt == OTA_EVT_COMPLETE) && (status == ZCL_STA_SUCCESS)) {
		LOG_INF("OTA image downloaded, rebooting into MCUboot");
		ota_mcuReboot();
	}
}

static ota_callBack_t app_ota_cb = {
	.processMsgCbFunc = app_ota_event,
};
#endif

/* ------------------------------------------------------------------ */
/* ZCL cluster info table (for zcl_register)                          */
/* ------------------------------------------------------------------ */

static zcl_specClusterInfo_t app_cluster_info[] = {
	{
		.clusterId = ZCL_CLUSTER_GEN_BASIC,
		.manuCode = 0U,
		.attrNum = APP_BASIC_ATTR_NUM,
		.attrTbl = app_basic_attr_tbl,
		.clusterRegisterFunc = zcl_basic_register,
		.clusterAppCb = NULL,
	},
	{
		.clusterId = ZCL_CLUSTER_GEN_IDENTIFY,
		.manuCode = 0U,
		.attrNum = APP_IDENTIFY_ATTR_NUM,
		.attrTbl = app_identify_attr_tbl,
		.clusterRegisterFunc = zcl_identify_register,
		.clusterAppCb = NULL,
	},
#if defined(CONFIG_ZIGBEE_ZCL_ON_OFF)
	{
		.clusterId = ZCL_CLUSTER_GEN_ON_OFF,
		.manuCode = 0U,
		.attrNum = APP_ONOFF_ATTR_NUM,
		.attrTbl = app_onoff_attr_tbl,
		.clusterRegisterFunc = zcl_onOff_register,
		.clusterAppCb = app_onoff_cmd,
	},
#endif
};

#define APP_CLUSTER_NUM ((u8)ARRAY_SIZE(app_cluster_info))

/* ------------------------------------------------------------------ */
/* Public API                                                          */
/* ------------------------------------------------------------------ */

void app_profile_register(void)
{
	memcpy(&app_basic_mfr_name[1], APP_PROFILE_MFR_NAME, sizeof(APP_PROFILE_MFR_NAME));
	memcpy(&app_basic_model_id[1], APP_PROFILE_MODEL_ID, sizeof(APP_PROFILE_MODEL_ID));

#if defined(CONFIG_ZIGBEE_ZCL_ON_OFF)
	if (gpio_is_ready_dt(&app_led)) {
		gpio_pin_configure_dt(&app_led, GPIO_OUTPUT_INACTIVE);
	}
#endif

	zcl_init(NULL);

	if (af_simpleDescGet(APP_PROFILE_ENDPOINT) == NULL) {
		if (!af_endpointRegister(APP_PROFILE_ENDPOINT, &app_simple_desc,
					 (af_endpoint_cb_t)zcl_rx_handler, NULL)) {
			LOG_WRN("app_profile: endpoint %u register failed", APP_PROFILE_ENDPOINT);
		}
	}

	zcl_register(APP_PROFILE_ENDPOINT, APP_CLUSTER_NUM, app_cluster_info);

#if defined(CONFIG_ZIGBEE_WWAH)
	wwah_init(WWAH_TYPE_SERVER, &app_simple_desc);
#endif

#if defined(CONFIG_ZIGBEE_OTA)
	ota_init(OTA_TYPE_CLIENT, &app_simple_desc, &app_ota_preamble, &app_ota_cb);
	ota_queryStart(OTA_PERIODIC_QUERY_INTERVAL);
#endif
}

/*
 * Override the optional hook in zb_bdb_bootstrap.c so that BDB init
 * picks up our real ZCL-wired endpoint descriptor.
 */
void zb_platform_app_register_endpoints(void)
{
#if !defined(CONFIG_ZIGBEE_NCP)
	/* An NCP host registers the endpoints it serves. */
	app_profile_register();
#endif

#if defined(CONFIG_ZIGBEE_GP)
	/*
	 * Vendor ordering (tl_zigbee_sdk apps/sampleGW/sampleGateway.c):
	 * gp_init() runs after the app's own endpoint/cluster registration.
	 */
	gp_init(APP_PROFILE_ENDPOINT);
#endif
}

/*
 * Provide the identity hooks used by the Basic-cluster interview fallback,
 * keeping the answers consistent with the real ZCL attribute table. The
 * strings are plain C strings (not ZCL length-prefixed).
 */
const void *app_profile_get_simple_desc(void)
{
	return &app_simple_desc;
}

const char *app_profile_mfr_name(void)
{
	return APP_PROFILE_MFR_NAME;
}

const char *app_profile_model_id(void)
{
	return APP_PROFILE_MODEL_ID;
}
```

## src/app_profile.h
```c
/*
 * SPDX-FileCopyrightText: Copyright The Zephyr Project Contributors
 * SPDX-License-Identifier: Apache-2.0
 */
/*
 * app_profile.h — Authoritative endpoint / profile / cluster definitions
 * for the zigbee_shell sample.
 *
 * External device contract (locked):
 *   HA profile 0x0104 · device ID 0x0000 · endpoint 1
 *   In-clusters: Basic (0x0000), Identify (0x0003)
 */
#pragma once

/* Profile identity */
#define APP_PROFILE_HA_PROFILE_ID   0x0104U
#define APP_PROFILE_HA_DEVICE_ID    0x0000U
#define APP_PROFILE_ENDPOINT        0x01U

/* Authoritative identity strings (single source of truth) */
#if defined(CONFIG_SOC_FAMILY_TELINK_TLSR)
#define APP_PROFILE_MFR_NAME        "Telink"
#elif defined(CONFIG_SOC_FAMILY_ESPRESSIF_ESP32)
#define APP_PROFILE_MFR_NAME        "Espressif"
#elif defined(CONFIG_SOC_FAMILY_NORDIC_NRF)
#define APP_PROFILE_MFR_NAME        "Nordic Semiconductors"
#else
#define APP_PROFILE_MFR_NAME        "Unknown"
#endif

#if defined(CONFIG_SOC)
#define APP_PROFILE_SOC_NAME        CONFIG_SOC
#else
#define APP_PROFILE_SOC_NAME        "unknown"
#endif

#if defined(CONFIG_ZIGBEE_ROUTER) || defined(CONFIG_ZIGBEE_COORDINATOR)
#define APP_PROFILE_ZIGBEE_ROLE     "router"
#else
#define APP_PROFILE_ZIGBEE_ROLE     "ed"
#endif

#define APP_PROFILE_MODEL_ID        APP_PROFILE_SOC_NAME "-zigbee-" APP_PROFILE_ZIGBEE_ROLE

/*
 * Initialize the ZCL layer and register the application endpoint.
 * Calls zcl_init(), af_endpointRegister(..., zcl_rx_handler, NULL),
 * and zcl_register() for the Basic and Identify clusters.
 *
 * Must be called before zb_platform_bdb_init_default().
 */
void app_profile_register(void);

/* Return a pointer to the static simple descriptor. */
const void *app_profile_get_simple_desc(void);

/* Single source of truth for interview-path identity strings. */
const char *app_profile_mfr_name(void);
const char *app_profile_model_id(void);
```

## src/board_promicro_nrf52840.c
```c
/*
 * SPDX-FileCopyrightText: Copyright The Zephyr Project Contributors
 * SPDX-License-Identifier: Apache-2.0
 */

#include <hal/nrf_power.h>
#include <zephyr/shell/shell.h>
#include <zephyr/sys/reboot.h>
#if defined(CONFIG_ZIGBEE_ED)
#include "zb_common.h"
#endif

static void enter_uf2(void)
{
	NRF_POWER->GPREGRET = 0x57U;
	sys_reboot(SYS_REBOOT_COLD);
}

static int cmd_uf2(const struct shell *shell, size_t argc, char **argv)
{
	ARG_UNUSED(shell);
	ARG_UNUSED(argc);
	ARG_UNUSED(argv);

	enter_uf2();
	return 0;
}

SHELL_CMD_REGISTER(uf2, NULL, "Reboot into the UF2 bootloader", cmd_uf2);

#if defined(CONFIG_ZIGBEE_ED)
static int cmd_zb_diag(const struct shell *shell, size_t argc, char **argv)
{
	ARG_UNUSED(argc);
	ARG_UNUSED(argv);

	shell_print(shell, "MAC RX unicast: %u, TX unicast: %u", g_sysDiags.macRxUcast,
		    g_sysDiags.macTxUcast);
	shell_print(shell, "NWK decrypt failures: %u, frame counter failures: %u",
		    g_sysDiags.nwkDecryptFailures, g_sysDiags.nwkFCFailure);
	shell_print(shell, "APS decrypt failures: %u, frame counter failures: %u",
		    g_sysDiags.apsDecryptFailures, g_sysDiags.apsFCFailure);
	shell_print(shell, "Buffer allocation failures: %u", g_sysDiags.packetBufferAllocateFailures);
	return 0;
}

SHELL_CMD_REGISTER(zb_diag, NULL, "Show Zigbee diagnostics", cmd_zb_diag);
#endif
```

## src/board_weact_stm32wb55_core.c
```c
/*
 * SPDX-FileCopyrightText: Copyright The Zephyr Project Contributors
 * SPDX-License-Identifier: Apache-2.0
 */

/*
 * Support for the WeAct STM32WB55 core board: the USB CDC ports (console and shell on the first,
 * mcumgr or the Z-Stack host on the second) and the watchdog. Runs from SYS_INIT, so main() stays
 * the same as on the other boards.
 */

#include <zephyr/device.h>
#include <zephyr/drivers/watchdog.h>
#include <zephyr/init.h>
#include <zephyr/kernel.h>

#ifdef CONFIG_USB_DEVICE_STACK_NEXT
#include <sample_usbd.h>
#include <zephyr/usb/usbd.h>
#endif

/*
 * The watchdog keeps counting in Standby: a deep-sleep device must not be reset by it, so its
 * timeout has to cover the longest sleep. 30 s is near the limit of the IWDG.
 */
#ifdef CONFIG_ZIGBEE_SLEEPY_DEEP
#define WDT_TIMEOUT_MS	30000U
/* A shorter period would wake the CPU too often for the deep sleep state to be chosen */
#define WDT_FEED_MS	10000
BUILD_ASSERT(CONFIG_ZIGBEE_ED_POLL_INTERVAL_MS <= 25000,
	     "the poll interval must stay below the watchdog timeout");
#else
#define WDT_TIMEOUT_MS	8000U
#define WDT_FEED_MS	1000
#endif

/*
 * A hung M4 resets itself after the timeout, so MCUboot opens its update window again and the
 * image can be replaced over the serial port without touching the board.
 */
static void wdt_thread(void *a, void *b, void *c)
{
	const struct device *wdt = DEVICE_DT_GET(DT_ALIAS(watchdog0));
	struct wdt_timeout_cfg cfg = {
		.window = { .min = 0U, .max = WDT_TIMEOUT_MS },
		.flags = WDT_FLAG_RESET_SOC,
	};
	int ch;

	ARG_UNUSED(a);
	ARG_UNUSED(b);
	ARG_UNUSED(c);

	ch = wdt_install_timeout(wdt, &cfg);
	if (ch < 0 || wdt_setup(wdt, WDT_OPT_PAUSE_HALTED_BY_DBG) != 0) {
		return;
	}

	for (;;) {
		wdt_feed(wdt, ch);
		k_msleep(WDT_FEED_MS);
	}
}

K_THREAD_DEFINE(wdt_tid, 512, wdt_thread, NULL, NULL, NULL, K_LOWEST_APPLICATION_THREAD_PRIO, 0, 0);

#ifdef CONFIG_USB_DEVICE_STACK_NEXT
static int usb_start(void)
{
	struct usbd_context *usbd = sample_usbd_init_device(NULL);

	if (usbd == NULL) {
		return -ENODEV;
	}

	return usbd_enable(usbd);
}
SYS_INIT(usb_start, APPLICATION, 90);
#endif
```
